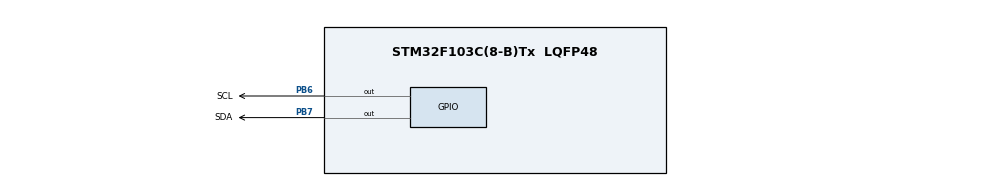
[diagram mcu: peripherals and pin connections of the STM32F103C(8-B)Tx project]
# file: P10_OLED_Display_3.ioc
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Mcu.Family=STM32F1
Mcu.Name=STM32F103C(8-B)Tx
Mcu.Package=LQFP48
NVIC.PriorityGroup=NVIC_PRIORITYGROUP_4
PB6.GPIO_Label=SCL
PB6.GPIO_ModeDefaultOutputPP=GPIO_MODE_OUTPUT_OD
PB6.GPIO_PuPd=GPIO_PULLUP
PB6.GPIO_Speed=GPIO_SPEED_FREQ_HIGH
PB6.PinState=GPIO_PIN_SET
PB6.Signal=GPIO_Output
PB7.GPIO_Label=SDA
PB7.GPIO_ModeDefaultOutputPP=GPIO_MODE_OUTPUT_OD
PB7.GPIO_PuPd=GPIO_PULLUP
PB7.GPIO_Speed=GPIO_SPEED_FREQ_HIGH
PB7.PinState=GPIO_PIN_SET
PB7.Signal=GPIO_Output
PC14-OSC32_IN.Mode=LSE-External-Oscillator
PC14-OSC32_IN.Signal=RCC_OSC32_IN
PC15-OSC32_OUT.Mode=LSE-External-Oscillator
PC15-OSC32_OUT.Signal=RCC_OSC32_OUT
PD0-OSC_IN.Mode=HSE-External-Oscillator
PD0-OSC_IN.Signal=RCC_OSC_IN
PD1-OSC_OUT.Mode=HSE-External-Oscillator
PD1-OSC_OUT.Signal=RCC_OSC_OUT
ProjectManager.HeapSize=0x200
ProjectManager.StackSize=0x400
ProjectManager.TargetToolchain=MDK-ARM V5
RCC.APB1Freq_Value=8000000
RCC.APB2Freq_Value=8000000
VP_SYS_VS_ND.Mode=No_Debug
board=custom

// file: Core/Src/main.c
/* USER CODE BEGIN Header */
/**
  ******************************************************************************
  * @file           : main.c
  * @brief          : Main program body
  ******************************************************************************
  * @attention
  *
  * Copyright (c) 2023 STMicroelectronics.
  * All rights reserved.
  *
  * This software is licensed under terms that can be found in the LICENSE file
  * in the root directory of this software component.
  * If no LICENSE file comes with this software, it is provided AS-IS.
  *
  ******************************************************************************
  */
/* USER CODE END Header */
#include "main.h"
#include "gpio.h"

/* USER CODE BEGIN Includes */
#include "oled.h"
/* USER CODE END Includes */

void SystemClock_Config(void);

int main(void)
{

  /* MCU Configuration--------------------------------------------------------*/

  /* Reset of all peripherals, Initializes the Flash interface and the Systick. */
  HAL_Init();

  /* Configure the system clock */
  SystemClock_Config();

  /* Initialize all configured peripherals */
  MX_GPIO_Init();
  /* USER CODE BEGIN 2 */
    OLED_Init();                              /* 初始化OLED，函数内部已包含清屏 */
    OLED_ShowString(2, 4, "OLED TEST");       /* 第2行第4列开始显示，共9个字符，在16列内大致居中 */
  /* USER CODE END 2 */

  /* Infinite loop */
  while (1)
  {

  }
}

void SystemClock_Config(void)
{
  RCC_OscInitTypeDef RCC_OscInitStruct = {0};
  RCC_ClkInitTypeDef RCC_ClkInitStruct = {0};

  /** Initializes the RCC Oscillators according to the specified parameters
  * in the RCC_OscInitTypeDef structure.
  */
  RCC_OscInitStruct.OscillatorType = RCC_OSCILLATORTYPE_HSI;
  RCC_OscInitStruct.HSIState = RCC_HSI_ON;
  RCC_OscInitStruct.HSICalibrationValue = RCC_HSICALIBRATION_DEFAULT;
  RCC_OscInitStruct.PLL.PLLState = RCC_PLL_NONE;
  if (HAL_RCC_OscConfig(&RCC_OscInitStruct) != HAL_OK)
  {
    Error_Handler();
  }

  /** Initializes the CPU, AHB and APB buses clocks
  */
  RCC_ClkInitStruct.ClockType = RCC_CLOCKTYPE_HCLK|RCC_CLOCKTYPE_SYSCLK
                              |RCC_CLOCKTYPE_PCLK1|RCC_CLOCKTYPE_PCLK2;
  RCC_ClkInitStruct.SYSCLKSource = RCC_SYSCLKSOURCE_HSI;
  RCC_ClkInitStruct.AHBCLKDivider = RCC_SYSCLK_DIV1;
  RCC_ClkInitStruct.APB1CLKDivider = RCC_HCLK_DIV1;
  RCC_ClkInitStruct.APB2CLKDivider = RCC_HCLK_DIV1;

  if (HAL_RCC_ClockConfig(&RCC_ClkInitStruct, FLASH_LATENCY_0) != HAL_OK)
  {
    Error_Handler();
  }
}

void Error_Handler(void)
{
  __disable_irq();
  while (1)
  {
  }
}
